# MIK32 register map
Vendor: Mikron; Series: MIK32; File version: 1.0
Registers are 32-bit, read-write, reset 0x0 unless marked. A register's access mark holds for its fields unless they carry their own. Offsets are from the block's base; [hi:lo] are bit positions; 'fields as' and 'values as' point back to an identical list.

## TIMER16_0 — Регистры 16-разрядного таймера
Base 0x00081C00
Same registers: TIMER16_1 0x00082000, TIMER16_2 0x00082400
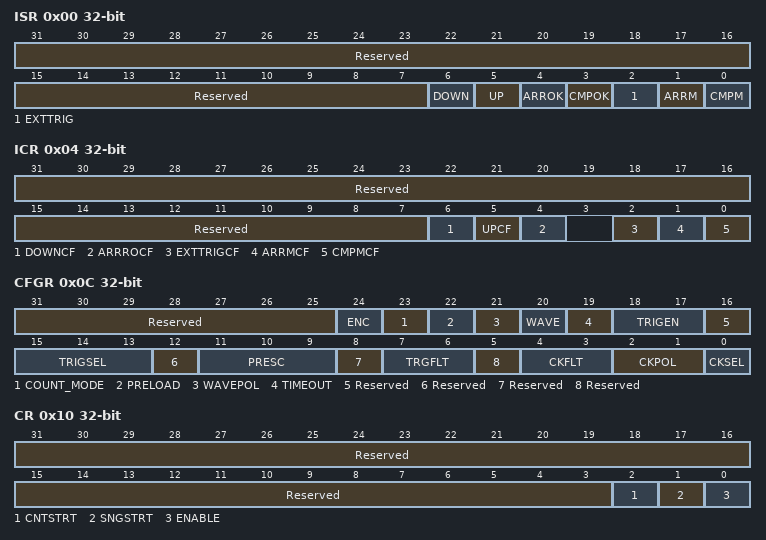
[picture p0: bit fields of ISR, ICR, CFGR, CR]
0x00 ISR ro — Регистр флагов прерываний
  [31:7] Reserved — Зарезервировано
  [6] DOWN — Изменение направления счетчика вверх на вниз. В режиме энкодера бит DOWN устанавливается аппаратно, чтобы сообщить приложению, что направление счетчика изменилось с "вверх" на "вниз".
  [5] UP — Изменение направления счетчика с вниз на вверх. В режиме энкодера бит UP устанавливается аппаратно, чтобы сообщить приложению, что направление счетчика изменилось с "вниз" на "вверх".
  [4] ARROK — Изменение направления счетчика с вниз на вверх. В режиме энкодера бит UP устанавливается аппаратно, чтобы сообщить приложению, что направление счетчика изменилось с "вниз" на "вверх".
  [3] CMPOK — Обновление регистра сравнения OK. CMPOK устанавливается аппаратными средствами, чтобы сообщить приложению, что операция записи в регистр CMP шины APB успешно завершена.
  [2] EXTTRIG — Cобытие фронта внешнего триггера. EXTTRIG устанавливается аппаратно, чтобы сообщить приложению, что на выбранном входе внешнего триггера возник достоверный фронт импульса. Если триггер игнорируется, так как таймер уже запущен, то этот флаг не устанавливается
  [1] ARRM — Cоответствие автозагрузки. ARRM устанавливается аппаратурой, чтобы сообщить приложению, что значение регистра CNT достигло значения регистра ARR.
  [0] CMPM — Совпадение сравнения. Бит CMPM устанавливается аппаратными средствами, чтобы сообщить приложению, что значение регистра CNT достигло значения регистра CMP
0x04 ICR wo write-1-clears — Регистр сброса флагов прерываний
  [31:7] Reserved — Зарезервировано
  [6] DOWNCF write-1-clears — Запись «1» в этот бит снимает флаг DOWN в регистре LPT_ISR
  [5] UPCF write-1-clears — Запись «1» в этот бит снимает флаг UP в регистре LPT_ISR
  [4] ARRROCF write-1-clears — Запись «1» в этот бит снимает флаг ARROK в регистре LPT_ISR
  [2] EXTTRIGCF write-1-clears — Запись «1» в этот бит снимает флаг EXTTRIG в регистре LPT_ISR
  [1] ARRMCF write-1-clears — Запись «1» в этот бит снимает флаг ARRM в регистре LPT_ISR
  [0] CMPMCF write-1-clears — Запись «1» в этот бит снимает флаг CMPM в регистре LPT_ISR
0x08 IER — Регистр разрешения прерываний
  [31:7] Reserved — Зарезервировано
  [6] DOWNIE — запрет/разрешение прерывания DOWN
    0=Disable (Прерывание запрешено); 1=Enable (Прерывание разрешено)
  [5] UPIE — запрет/разрешение прерывания UP
    values as DOWNIE
  [5] ARRMIE — запрет/разрешение прерывания ARRM
    values as DOWNIE
  [4] ARROKIE — запрет/разрешение прерывания ARRROK
    values as DOWNIE
  [3] CMPOKIE — запрет/разрешение прерывания CMPOK
    values as DOWNIE
  [2] EXTTRIGIE — запрет/разрешение прерывания EXTTRIG
    values as DOWNIE
  [0] CMPMIE — запрет/разрешение прерывания CMPM
    values as DOWNIE
0x0C CFGR — Регистр конфигурации
  [31:25] Reserved — Зарезервировано
  [24] ENC — Разрешение режима энкодера. Бит ENC управляет режимом работы энкодера
    0=Disable (Режим энкодера отключен); 1=Enable (Режим энэнкодера включен)
  [23] COUNT_MODE — Бит COUNTMODE выбирает, какой источник тактового сигнала используется TIMER16 для синхронизации счетчика
    0=Internal (Счетчик инкрементируется после каждого внутреннего тактового импульса); 1=External (Счетчик увеличивается после каждого действительного тактового импульса на внешнем lnput1 TIMER16)
  [22] PRELOAD — Режим обновления регистров. Бит PRELOAD управляет модальностью обновления регистров ARR и CMP
    0=After_write (Регистры обновляются после каждого доступа к записи на шине APB); 1=End_period (Регистры обновляются в конце текущего периода TIMER16)
  [21] WAVEPOL — Полярность формы волны. Бит WAVEPOL управляет полярностью выходного сигнала
    0=Noninverted (Выход TIMER16 отражает результаты сравнения между регистрами ARR и CMP); 1=Inverted (Выход TIMER16 отражает инверсные результаты сравнения между регистрами ARR и CMP)
  [20] WAVE — Форма волны. Бит WAVE управляет формой выходного сигнала
    0=PWM_or_OneShot (Деактивировать режим Set-once, форма волны ШИМ (PWM) / один импульс (One shot)); 1=Set_once (Активировать режим Set-once)
  [19] TIMEOUT — Разрешение тайм-аута. Бит TIMOUT управляет функцией тайм-аута
    0=Trigger_event_ignor (Триггерное событие, поступающее, когда таймер уже запущен, будет проигнорировано); 1=Trigger_event_restart (Триггерное событие, поступающее, когда таймер уже запущен, сбросит и перезапустит счетчик)
  [18:17] TRIGEN — Разрешение и полярность триггера.Бит TRIGEN управляет тем, запускается ли счетчик TIMER16 внешним триггером или нет. Если выбрана опция внешнего запуска, возможны три конфигурации активного фронта триггера
    0=Software (Программный триггер (начало отсчета инициируется программно)); 1=Rising (Нарастающий фронт является активным фронтом); 2=Folling (Падающий фронт является активным фронтом); 0=Both_edge (Оба фронта являются активными фронтами энергопотреблением)
  [16] Reserved — Зарезервировано
  [15:13] TRIGSEL — Селектор триггера. Биты TRIGSEL выбирают источник триггера, который будет служить событием запуска для TIMER16, из 8 доступных источников.
    0=GPIO0_7 (Источник триггера GPIO0_7); 1=GPIO0_4 (Источник триггера GPIO0_4); 2=GPIO0_15 (Источник триггера GPIO0_15); 3=GPIO0_14 (Источник триггера GPIO0_14); 4=TSENS (Источник триггера - окончание преобразования термосенсора); 5=ADC (окончание преобразования АЦП); 6=RTC_IRQ (Источник триггера - прерывание RTC); 7=ALARM (Будильник)
  [12] Reserved — Зарезервировано
  [11:9] PRESC — Делитель частоты. Биты PRESC задают коэффициент деления делителя. /n
    0=Делитель 1; 1=Делитель 2; 2=Делитель 4; 3=Делитель 8; 4=Делитель 16; 5=Делитель 32; 6=Делитель 64; 7=Делитель 128
  [8] Reserved — Зарезервировано
  [7:6] TRGFLT — Конфигурируемый цифровой фильтр для триггера. Значение TRGFLT устанавливает количество последовательных одинаковых выборок, которые должны быть обнаружены при изменении уровня на внутреннем триггере, прежде чем это будет считаться действительным переходом уровня. Для использования этой функции необходимо наличие источника внутреннего тактового сигнала.
    0=Disable (Любое изменение активного уровня триггера читается действительным триггером); 1=2CLOCK (Изменение активного уровня триггера должно быть стабильным в течение не менее 2 тактовых периодов, прежде чем он будет считаться действительным триггером.); 2=4CLOCK (Изменение активного уровня триггера должно быть стабильным в течение как минимум 4 тактовых периодов, прежде чем он будет считаться действительным триггером); 3=8CLOCK (Изменение активного уровня триггера должно быть стабильным в течение не менее 8 тактовых периодов, прежде чем он будет считаться действительным триггером)
  [5] Reserved — Зарезервировано
  [4:3] CKFLT — Конфигурируемый цифровой фильтр для внешнего тактового генератора. Значение CKFLT устанавливает количество последовательных одинаковых выборок, которые должны быть обнаружены при изменении уровня внешнего тактового сигнала, прежде чем это будет считаться действительным переходом уровня. Для ис-пользования этой функции необходимо наличие внутреннего источника тактового сигнала.
    values as TRGFLT
  [2:1] CKPOL — Полярность синхронизации. Когда TIMER16 тактируется внешним ис-точником тактового сигнала, биты CKPOL используются для настройки активного фронта или фронтов, ис-пользуемых счетчиком
    0=Rising (Нарастающий фронт является активным фронтом, используемым для подсчета); 1=Folling (Спадающий фронт является активным фронтом, используемым для подсчета); 2=Both_edge (Оба фронта являются активными фронтами. Когда оба фронта внешнего тактового сигнала считаются активными, TIMER16 должен также тактироваться внутренним источником тактового сигнала с частотой, по крайней мере в четыре раза превышающей частоту внешнего тактового сигнала.)
  [0] CKSEL — Селектор тактовых импульсов. Бит CKSEL выбирает, какой источник тактовых импульсов будет использо-вать TIMER16
    0=Internal (TIMER16 тактируется внутренним источником тактового сигнала (APB тактовый генератор или любой из встроенных генераторов)); 1=External (TIMER16 тактируется внешним источником тактового сигнала через внешний lnput1 TIMER16)
0x10 CR — Регистр управления
  [31:3] Reserved — Зарезервировано
  [2] CNTSTRT — Запуск таймера в непрерывном режиме Этот бит устанавливается программно и очищается аппаратно. В случае программного запуска (TRIGEN[1:0] = '00'), установка этого бита запускает TIMER16 в непрерывном режиме. Если программный запуск отключен (TRIGEN[1:0] отличен от '00'), установка этого бита запускает таймер в непрерывном режиме, как только будет обнаружен внешний триггер. Если этот бит установлен, когда идет счет в режиме одиночного импульса, то таймер не остановится при очередном совпадении регистров ARR и CNT, и счетчик TIMER16 продолжит счет в непрерывном режиме. Этот бит может быть установлен только при включенном TIMER16. Он будет автоматически сброшен аппаратными средствами.
  [1] SNGSTRT — Запуск TIMER16 в одиночном режиме Этот бит устанавливается программно и очищается аппаратно. В случае программного запуска (TRIGEN[1:0] = '00'), установка этого бита запускает TIMER16 в режиме одиночного импульса. Если про-граммный запуск отключен (TRIGEN[1:0] отличен от '00'), уста-новка этого бита запускает TIMER16 в режиме одиночного импульса, как только обнаруживается внешний триг-гер. Если этот бит установлен, когда TIMER16 находится в режиме непре-рывного счета, то TIMER16 остано-вится при следующем совпадении ре-гистров ARR и CNT. Этот бит может быть установлен только при включенном TIMER16. Он будет автоматически сброшен аппа-ратными средствами.
  [0] ENABLE — Разрешение TIMER16. Бит ENABLE устанавливается и очищается программно
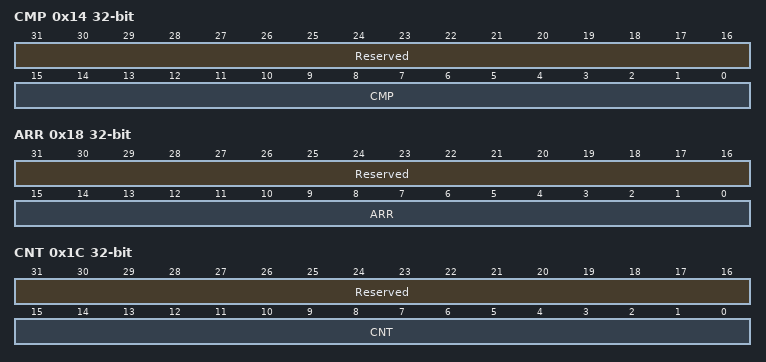
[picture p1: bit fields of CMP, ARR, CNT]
0x14 CMP — Регистр сравнения. Примечание: Регистр CMP может быть изменен только тогда, когда TIMER16 включен (бит ENABLE установлен в '1').
  [31:16] Reserved — Зарезервировано
  [15:0] CMP — Сравниваемое значение. CMP - это значение сравнения, используемое TIMER16. Примечание: Регистр CMP может быть изменен только тогда, когда TIMER16 включен (бит ENABLE установлен в '1').
0x18 ARR — Регистр автоматической перезагрузки. Примечание: Регистр CMP может быть изменен только тогда, когда TIMER16 включен (бит ENABLE установлен в '1').
  [31:16] Reserved — Зарезервировано
  [15:0] ARR — Значение автоматической перезагрузки ARR - значение автозагрузки для TIMER16. Это значение должно быть строго больше, чем значение CMP[15:0]. Примечание: Регистр ARR может быть изменен только тогда, когда TIMER16 включен (бит ENABLE установлен в '1').
0x1C CNT ro — Регистр счётчика
  [31:16] Reserved — Зарезервировано
  [15:0] CNT — Значение счетчика. Когда TIMER16 работает с асинхронными тактовыми сигналами, чтение регистра CNT мо-жет вернуть недостоверные значения. Поэтому в этом случае необходимо выполнить два последовательных до-ступа на чтение и убедиться, что два возвращенных значения идентичны.
